# ATSAM4CMS16C_1 register map
Vendor: Atmel; Series: SAM4CM; File version: 0
CPU: CM4 r0p0, selectable endian, no MPU, FPU, 4 interrupt priority bits
Registers are 32-bit, read-write, reset 0x0 unless marked. A register's access mark holds for its fields unless they carry their own. Offsets are from the block's base; [hi:lo] are bit positions.

## UART0 — Universal Asynchronous Receiver Transmitter 0
Base 0x400E0600; register names take the prefix UART0_
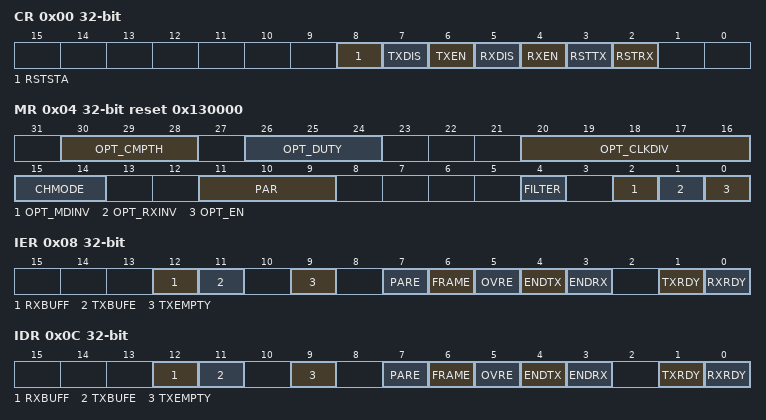
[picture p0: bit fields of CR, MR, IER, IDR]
0x00 CR wo reset not defined — Control Register
  [8] RSTSTA — Reset Status
  [7] TXDIS — Transmitter Disable
  [6] TXEN — Transmitter Enable
  [5] RXDIS — Receiver Disable
  [4] RXEN — Receiver Enable
  [3] RSTTX — Reset Transmitter
  [2] RSTRX — Reset Receiver
0x04 MR reset 0x130000 — Mode Register
  [30:28] OPT_CMPTH — Receive Path Comparator Threshold
    0=VDDIO_DIV2 (Comparator threshold is VDDIO/2 volts.); 1=VDDIO_DIV2P5 (Comparator threshold is VDDIO/2.5 volts.); 2=VDDIO_DIV3P3 (Comparator threshold is VDDIO/3.3 volts.); 3=VDDIO_DIV5 (Comparator threshold is VDDIO/5 volts.); 4=VDDIO_DIV10 (Comparator threshold is VDDIO/10 volts.)
  [26:24] OPT_DUTY — Optical Link Modulation Clock Duty Cycle
    0=DUTY_50 (Modulation clock duty cycle Is 50%.); 1=DUTY_43P75 (Modulation clock duty cycle Is 43.75%.); 2=DUTY_37P5 (Modulation clock duty cycle Is 37.5%.); 3=DUTY_31P25 (Modulation clock duty cycle Is 31.75%.); 4=DUTY_25 (Modulation clock duty cycle Is 25%.); 5=DUTY_18P75 (Modulation clock duty cycle Is 18.75%.); 6=DUTY_12P5 (Modulation clock duty cycle Is 12.5%.); 7=DUTY_6P25 (Modulation clock duty cycle Is 6.25%.)
  [20:16] OPT_CLKDIV — Optical Link Clock Divider
  [15:14] CHMODE — Channel Mode
    0=NORMAL (Normal mode); 1=AUTOMATIC (Automatic echo); 2=LOCAL_LOOPBACK; 3=REMOTE_LOOPBACK
  [11:9] PAR — Parity Type
    0=EVEN (Even Parity); 1=ODD (Odd Parity); 2=SPACE (Space: parity forced to 0); 3=MARK (Mark: parity forced to 1); 4=NO (No parity)
  [4] FILTER — Receiver Digital Filter
    0=DISABLED (UART does not filter the receive line.); 1=ENABLED (UART filters the receive line using a three-sample filter (16x-bit clock) (2 over 3 majority).)
  [2] OPT_MDINV — UART Modulated Data Inverted
    0=DISABLED (The output of the modulator is not inverted.); 1=ENABLED (The output of the modulator is inverted.)
  [1] OPT_RXINV — UART Receive Data Inverted
    0=DISABLED (The comparator data output is not inverted before entering UART.); 1=ENABLED (The comparator data output is inverted before entering UART.)
  [0] OPT_EN — UART Optical Interface Enable
    0=DISABLED (The UART transmitter data is not inverted before modulation.); 1=ENABLED (The UART transmitter data is inverted before modulation.)
0x08 IER wo reset not defined — Interrupt Enable Register
  [12] RXBUFF — Enable Buffer Full Interrupt
  [11] TXBUFE — Enable Buffer Empty Interrupt
  [9] TXEMPTY — Enable TXEMPTY Interrupt
  [7] PARE — Enable Parity Error Interrupt
  [6] FRAME — Enable Framing Error Interrupt
  [5] OVRE — Enable Overrun Error Interrupt
  [4] ENDTX — Enable End of Transmit Interrupt
  [3] ENDRX — Enable End of Receive Transfer Interrupt
  [1] TXRDY — Enable TXRDY Interrupt
  [0] RXRDY — Enable RXRDY Interrupt
0x0C IDR wo reset not defined — Interrupt Disable Register
  [12] RXBUFF — Disable Buffer Full Interrupt
  [11] TXBUFE — Disable Buffer Empty Interrupt
  [9] TXEMPTY — Disable TXEMPTY Interrupt
  [7] PARE — Disable Parity Error Interrupt
  [6] FRAME — Disable Framing Error Interrupt
  [5] OVRE — Disable Overrun Error Interrupt
  [4] ENDTX — Disable End of Transmit Interrupt
  [3] ENDRX — Disable End of Receive Transfer Interrupt
  [1] TXRDY — Disable TXRDY Interrupt
  [0] RXRDY — Disable RXRDY Interrupt
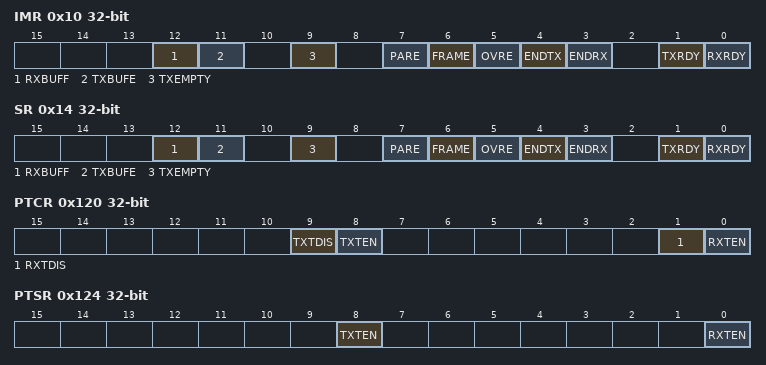
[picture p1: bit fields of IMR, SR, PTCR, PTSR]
0x10 IMR ro — Interrupt Mask Register
  [12] RXBUFF — Mask RXBUFF Interrupt
  [11] TXBUFE — Mask TXBUFE Interrupt
  [9] TXEMPTY — Mask TXEMPTY Interrupt
  [7] PARE — Mask Parity Error Interrupt
  [6] FRAME — Mask Framing Error Interrupt
  [5] OVRE — Mask Overrun Error Interrupt
  [4] ENDTX — Mask End of Transmit Interrupt
  [3] ENDRX — Mask End of Receive Transfer Interrupt
  [1] TXRDY — Disable TXRDY Interrupt
  [0] RXRDY — Mask RXRDY Interrupt
0x14 SR ro reset not defined — Status Register
  [12] RXBUFF — Receive Buffer Full
  [11] TXBUFE — Transmission Buffer Empty
  [9] TXEMPTY — Transmitter Empty
  [7] PARE — Parity Error
  [6] FRAME — Framing Error
  [5] OVRE — Overrun Error
  [4] ENDTX — End of Transmitter Transfer
  [3] ENDRX — End of Receiver Transfer
  [1] TXRDY — Transmitter Ready
  [0] RXRDY — Receiver Ready
0x18 RHR ro — Receive Holding Register
  [7:0] RXCHR — Received Character
0x1C THR wo reset not defined — Transmit Holding Register
  [7:0] TXCHR — Character to be Transmitted
0x20 BRGR — Baud Rate Generator Register
  [15:0] CD — Clock Divisor
0x100 RPR — Receive Pointer Register
  [31:0] RXPTR
0x104 RCR — Receive Counter Register
  [15:0] RXCTR
0x108 TPR — Transmit Pointer Register
  [31:0] TXPTR — Transmit Counter Register
0x10C TCR — Transmit Counter Register
  [15:0] TXCTR
0x110 RNPR — Receive Next Pointer Register
  [31:0] RXNPTR — Receive Next Pointer
0x114 RNCR — Receive Next Counter Register
  [15:0] RXNCTR — Receive Next Counter
0x118 TNPR — Transmit Next Pointer Register
  [31:0] TXNPTR — Transmit Next Pointer
0x11C TNCR — Transmit Next Counter Register
  [15:0] TXNCTR — Transmit Counter Next
0x120 PTCR wo — Transfer Control Register
  [9] TXTDIS — Transmitter Transfer Disable
  [8] TXTEN — Transmitter Transfer Enable
  [1] RXTDIS — Receiver Transfer Disable
  [0] RXTEN — Receiver Transfer Enable
0x124 PTSR ro — Transfer Status Register
  [8] TXTEN — Transmitter Transfer Enable
  [0] RXTEN — Receiver Transfer Enable

## UART1 — Universal Asynchronous Receiver Transmitter 1
Base 0x48004000; register names take the prefix UART1_
Registers as UART0.
